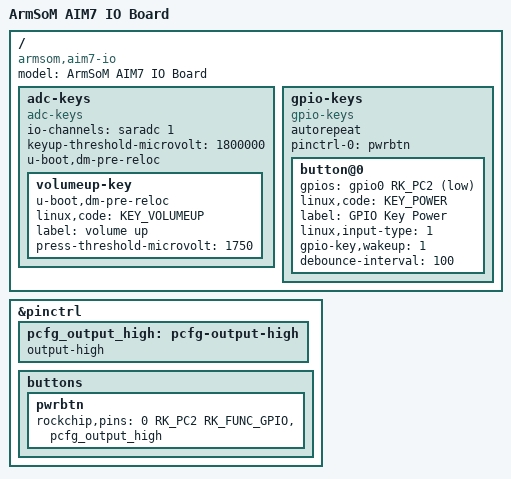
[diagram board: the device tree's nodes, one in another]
// SPDX-License-Identifier: (GPL-2.0+ OR MIT)
/*
 * Copyright (c) 2021 Rockchip Electronics Co., Ltd
 *
 */

/dts-v1/;
#include "rk3588.dtsi"
#include "rk3588-u-boot.dtsi"
#include <dt-bindings/input/input.h>

/ {
	model = "ArmSoM AIM7 IO Board";
	compatible = "armsom,aim7-io", "rockchip,rk3588";

	adc-keys {
		compatible = "adc-keys";
		io-channels = <&saradc 1>;
		io-channel-names = "buttons";
		keyup-threshold-microvolt = <1800000>;
		u-boot,dm-pre-reloc;
		status = "okay";

		volumeup-key {
			u-boot,dm-pre-reloc;
			linux,code = <KEY_VOLUMEUP>;
			label = "volume up";
			press-threshold-microvolt = <1750>;
		};
	};

	gpio-keys {
		compatible = "gpio-keys";
		#address-cells = <1>;
		#size-cells = <0>;
		autorepeat;

		pinctrl-names = "default";
		pinctrl-0 = <&pwrbtn>;

		button@0 {
			gpios = <&gpio0 RK_PC2 GPIO_ACTIVE_LOW>;
			linux,code = <KEY_POWER>;
			label = "GPIO Key Power";
			linux,input-type = <1>;
			gpio-key,wakeup = <1>;
			debounce-interval = <100>;
		};
	};
};

&pinctrl {
	pcfg_output_high: pcfg-output-high {
		output-high;
	};

	buttons {
		pwrbtn: pwrbtn {
			rockchip,pins = <0 RK_PC2 RK_FUNC_GPIO &pcfg_output_high>;
		};
	};
};
